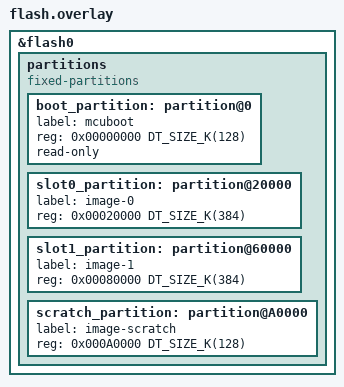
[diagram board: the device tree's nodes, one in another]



&flash0 {
	partitions {
		compatible = "fixed-partitions";
		#address-cells = <1>;
		#size-cells = <1>;

		/*
		 * 256KB for bootloader. This is too large but
		 * there is no way to make the part smaller.
		 */
		boot_partition: partition@0 {
			label = "mcuboot";
			reg = <0x00000000 DT_SIZE_K(128)>;
			read-only;
		};

		/* application image slot: 256KB */
		slot0_partition: partition@20000 {
			label = "image-0";
			reg = <0x00020000 DT_SIZE_K(384)>;
		};

		/* backup slot: 256KB */
		slot1_partition: partition@60000 {
			label = "image-1";
			reg = <0x00080000 DT_SIZE_K(384)>;
		};


		/* scratch slot: 256KB */
		scratch_partition: partition@A0000 {
			label = "image-scratch";
			reg = <0x000A0000 DT_SIZE_K(128)>;
		};

	};
};

			/*	storage_partition: partition@C0000 {
			label = "storage";
			reg = <0x000C0000 DT_SIZE_K(128)>;
		}; */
